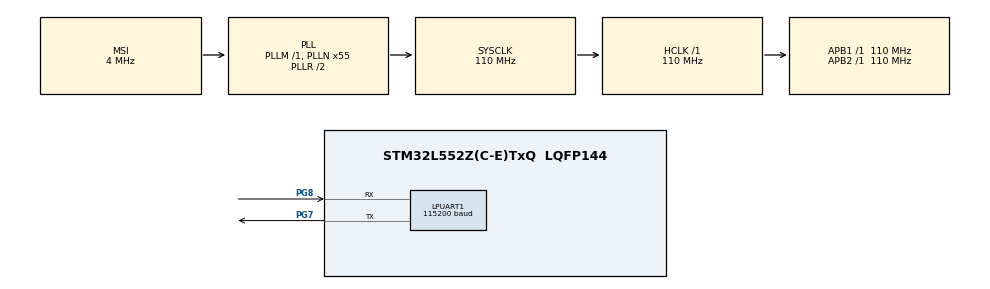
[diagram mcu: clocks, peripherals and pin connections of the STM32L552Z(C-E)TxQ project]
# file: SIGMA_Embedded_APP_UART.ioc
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LPUART1.BaudRate=115200
Mcu.Family=STM32L5
Mcu.Name=STM32L552Z(C-E)TxQ
Mcu.Package=LQFP144
Mcu.TrustZone=disable
NVIC.PriorityGroup=NVIC_PRIORITYGROUP_3
PG7.Mode=Asynchronous
PG7.Signal=LPUART1_TX
PG8.Mode=Asynchronous
PG8.Signal=LPUART1_RX
PH0-OSC_IN\ (PH0).Mode=HSE-External-Oscillator
PH0-OSC_IN\ (PH0).Signal=RCC_OSC_IN
PH1-OSC_OUT\ (PH1).Mode=HSE-External-Oscillator
PH1-OSC_OUT\ (PH1).Signal=RCC_OSC_OUT
ProjectManager.HeapSize=0x200
ProjectManager.StackSize=0x400
ProjectManager.TargetToolchain=STM32CubeIDE
RCC.ADCCLockSelection=RCC_ADCCLKSOURCE_SYSCLK
RCC.ADCFreq_Value=110000000
RCC.AHBFreq_Value=110000000
RCC.APB1Freq_Value=110000000
RCC.APB1TimFreq_Value=110000000
RCC.APB2Freq_Value=110000000
RCC.APB2TimFreq_Value=110000000
RCC.CK48CLockSelection=RCC_USBCLKSOURCE_HSI48
RCC.CortexFreq_Value=110000000
RCC.HCLKFreq_Value=110000000
RCC.HSE_VALUE=8000000
RCC.HSI48_VALUE=48000000
RCC.HSI_VALUE=16000000
RCC.MSI_VALUE=4000000
RCC.PLLN=55
RCC.PLLSAI1N=24
RCC.RTCClockSelection=RCC_RTCCLKSOURCE_LSE
RCC.SYSCLKFreq_VALUE=110000000
RCC.SYSCLKSource=RCC_SYSCLKSOURCE_PLLCLK
RCC.USBFreq_Value=48000000
RCC.VCOOutputFreq_Value=220000000
board=NUCLEO-L552ZE-Q

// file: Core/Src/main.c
/* USER CODE BEGIN Header */
/**
  ******************************************************************************
  * @file           : main.c
  * @brief          : Main program body
  ******************************************************************************
  * @attention
  *
  * Copyright (c) 2024 STMicroelectronics.
  * All rights reserved.
  *
  * This software is licensed under terms that can be found in the LICENSE file
  * in the root directory of this software component.
  * If no LICENSE file comes with this software, it is provided AS-IS.
  *
  ******************************************************************************
  */
/* USER CODE END Header */
#include "main.h"

/* USER CODE BEGIN PD */
static uart_status SIGMA_Uart_Transmit_str(uint8_t *data);
/* USER CODE END PD */

UART_HandleTypeDef hlpuart1;

void SystemClock_Config(void);
static void MX_GPIO_Init(void);
static void MX_LPUART1_UART_Init(void);

int main(void)
{

  /* MCU Configuration--------------------------------------------------------*/

  /* Reset of all peripherals, Initializes the Flash interface and the Systick. */
  HAL_Init();

  /* Configure the system clock */
  SystemClock_Config();

  /* Initialize all configured peripherals */
  MX_GPIO_Init();
  MX_LPUART1_UART_Init();
  /* USER CODE BEGIN 2 */
  SIGMA_Uart_Transmit_str((uint8_t*)"Hello I am Running the App now!");
  /* USER CODE END 2 */

  /* Infinite loop */
  while (1)
  {

  }
}

void SystemClock_Config(void)
{
  RCC_OscInitTypeDef RCC_OscInitStruct = {0};
  RCC_ClkInitTypeDef RCC_ClkInitStruct = {0};

  /** Configure the main internal regulator output voltage
  */
  if (HAL_PWREx_ControlVoltageScaling(PWR_REGULATOR_VOLTAGE_SCALE0) != HAL_OK)
  {
    Error_Handler();
  }

  /** Initializes the RCC Oscillators according to the specified parameters
  * in the RCC_OscInitTypeDef structure.
  */
  RCC_OscInitStruct.OscillatorType = RCC_OSCILLATORTYPE_MSI;
  RCC_OscInitStruct.MSIState = RCC_MSI_ON;
  RCC_OscInitStruct.MSICalibrationValue = RCC_MSICALIBRATION_DEFAULT;
  RCC_OscInitStruct.MSIClockRange = RCC_MSIRANGE_6;
  RCC_OscInitStruct.PLL.PLLState = RCC_PLL_ON;
  RCC_OscInitStruct.PLL.PLLSource = RCC_PLLSOURCE_MSI;
  RCC_OscInitStruct.PLL.PLLM = 1;
  RCC_OscInitStruct.PLL.PLLN = 55;
  RCC_OscInitStruct.PLL.PLLP = RCC_PLLP_DIV7;
  RCC_OscInitStruct.PLL.PLLQ = RCC_PLLQ_DIV2;
  RCC_OscInitStruct.PLL.PLLR = RCC_PLLR_DIV2;
  if (HAL_RCC_OscConfig(&RCC_OscInitStruct) != HAL_OK)
  {
    Error_Handler();
  }

  /** Initializes the CPU, AHB and APB buses clocks
  */
  RCC_ClkInitStruct.ClockType = RCC_CLOCKTYPE_HCLK|RCC_CLOCKTYPE_SYSCLK
                              |RCC_CLOCKTYPE_PCLK1|RCC_CLOCKTYPE_PCLK2;
  RCC_ClkInitStruct.SYSCLKSource = RCC_SYSCLKSOURCE_PLLCLK;
  RCC_ClkInitStruct.AHBCLKDivider = RCC_SYSCLK_DIV1;
  RCC_ClkInitStruct.APB1CLKDivider = RCC_HCLK_DIV1;
  RCC_ClkInitStruct.APB2CLKDivider = RCC_HCLK_DIV1;

  if (HAL_RCC_ClockConfig(&RCC_ClkInitStruct, FLASH_LATENCY_5) != HAL_OK)
  {
    Error_Handler();
  }
}

static void MX_LPUART1_UART_Init(void)
{

  hlpuart1.Instance = LPUART1;
  hlpuart1.Init.BaudRate = 115200;
  hlpuart1.Init.WordLength = UART_WORDLENGTH_8B;
  hlpuart1.Init.StopBits = UART_STOPBITS_1;
  hlpuart1.Init.Parity = UART_PARITY_NONE;
  hlpuart1.Init.Mode = UART_MODE_TX_RX;
  hlpuart1.Init.HwFlowCtl = UART_HWCONTROL_NONE;
  hlpuart1.Init.OneBitSampling = UART_ONE_BIT_SAMPLE_DISABLE;
  hlpuart1.Init.ClockPrescaler = UART_PRESCALER_DIV1;
  hlpuart1.AdvancedInit.AdvFeatureInit = UART_ADVFEATURE_NO_INIT;
  hlpuart1.FifoMode = UART_FIFOMODE_DISABLE;
  if (HAL_UART_Init(&hlpuart1) != HAL_OK)
  {
    Error_Handler();
  }
  if (HAL_UARTEx_SetTxFifoThreshold(&hlpuart1, UART_TXFIFO_THRESHOLD_1_8) != HAL_OK)
  {
    Error_Handler();
  }
  if (HAL_UARTEx_SetRxFifoThreshold(&hlpuart1, UART_RXFIFO_THRESHOLD_1_8) != HAL_OK)
  {
    Error_Handler();
  }
  if (HAL_UARTEx_DisableFifoMode(&hlpuart1) != HAL_OK)
  {
    Error_Handler();
  }

}

static void MX_GPIO_Init(void)
{

  /* GPIO Ports Clock Enable */
  __HAL_RCC_GPIOH_CLK_ENABLE();
  __HAL_RCC_GPIOG_CLK_ENABLE();
  HAL_PWREx_EnableVddIO2();

}

/* USER CODE BEGIN 4 */
/**
 * @brief   Transmits a string to UART.
 * @param   *data: Array of the data.
 * @return  status: Report about the success of the transmission.
 */
uart_status SIGMA_Uart_Transmit_str(uint8_t *data)
{
  uart_status status = UART_ERROR;
  uint16_t length = 0u;

  /* Calculate the length. */
  while ('\0' != data[length])
  {
    length++;
  }

  if (HAL_OK == HAL_UART_Transmit(&hlpuart1, data, length, UART_TIMEOUT))
  {
    status = UART_OK;
  }

  return status;
}
/* USER CODE END 4 */

void Error_Handler(void)
{
  __disable_irq();
  while (1)
  {
  }
}
